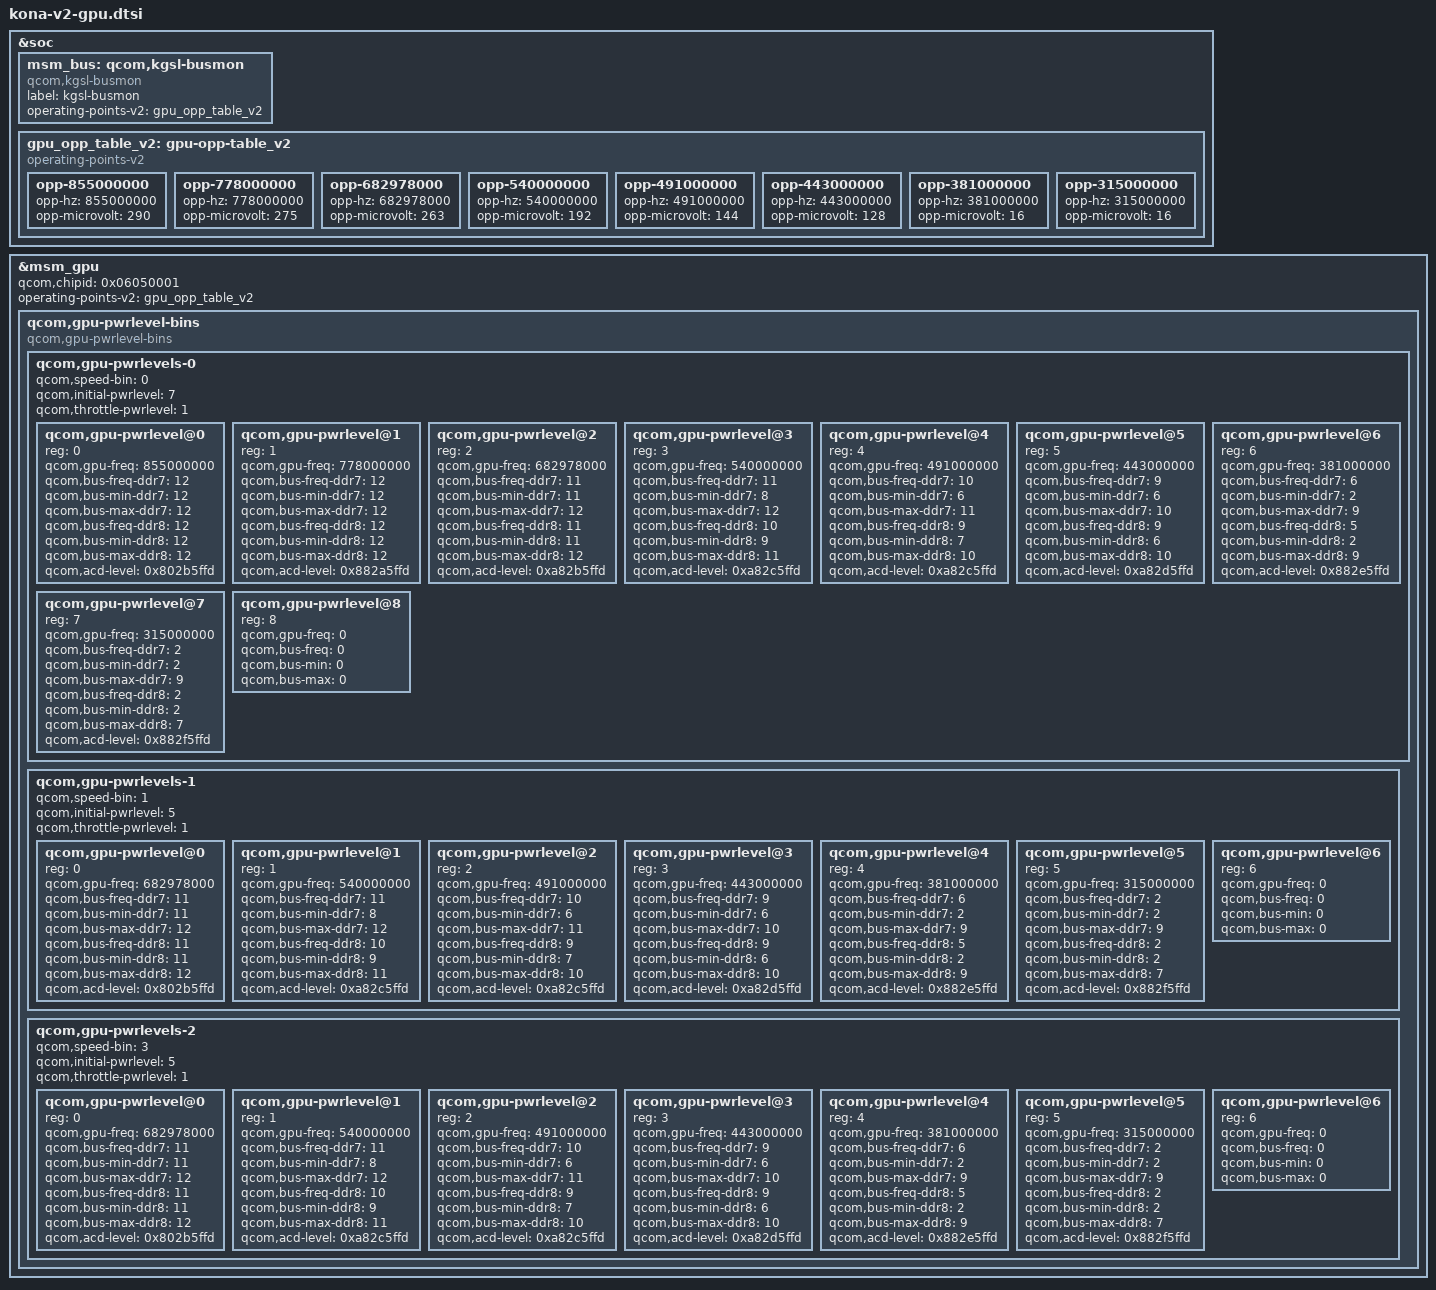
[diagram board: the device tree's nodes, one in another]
&soc {
	msm_bus: qcom,kgsl-busmon {
		label = "kgsl-busmon";
		compatible = "qcom,kgsl-busmon";
		operating-points-v2 = <&gpu_opp_table_v2>;
	};

	gpu_opp_table_v2: gpu-opp-table_v2 {
		compatible = "operating-points-v2";
		
		opp-855000000 {
			opp-hz = /bits/ 64 <855000000>;
			opp-microvolt = <290>;
		};
		
		opp-778000000 {
			opp-hz = /bits/ 64 <778000000>;
			opp-microvolt = <275>;
		};

		opp-682978000 {
			opp-hz = /bits/ 64 <682978000>;
			opp-microvolt = <263>;
		};

		opp-540000000 {
			opp-hz = /bits/ 64 <540000000>;
			opp-microvolt = <192>;
		};

		opp-491000000 {
			opp-hz = /bits/ 64 <491000000>;
			opp-microvolt = <144>;
		};

		opp-443000000 {
			opp-hz = /bits/ 64 <443000000>;
			opp-microvolt = <128>;
		};

		opp-381000000 {
			opp-hz = /bits/ 64 <381000000>;
			opp-microvolt = <16>;
		};

		opp-315000000 {
			opp-hz = /bits/ 64 <315000000>;
			opp-microvolt = <16>;
		};

	};
};

&msm_gpu {
	qcom,chipid = <0x06050001>;

	/* GPU OPP data */
	operating-points-v2 = <&gpu_opp_table_v2>;

	/delete-property/qcom,initial-pwrlevel;
	/delete-node/qcom,gpu-pwrlevels;

	/* Power levels bins */
	qcom,gpu-pwrlevel-bins {
		compatible="qcom,gpu-pwrlevel-bins";
		#address-cells = <1>;
		#size-cells = <0>;

		qcom,gpu-pwrlevels-0 {
			#address-cells = <1>;
			#size-cells = <0>;
			qcom,speed-bin = <0>;
			qcom,initial-pwrlevel = <7>;
			qcom,throttle-pwrlevel = <1>;

			qcom,gpu-pwrlevel@0 {
				reg = <0>;
				qcom,gpu-freq = <855000000>;
				qcom,bus-freq-ddr7 = <12>;
				qcom,bus-min-ddr7 = <12>;
				qcom,bus-max-ddr7 = <12>;

				qcom,bus-freq-ddr8 = <12>;
				qcom,bus-min-ddr8 = <12>;
				qcom,bus-max-ddr8 = <12>;

				qcom,acd-level = <0x802b5ffd>;
			};

			qcom,gpu-pwrlevel@1 {
				reg = <1>;
				qcom,gpu-freq = <778000000>;
				qcom,bus-freq-ddr7 = <12>;
				qcom,bus-min-ddr7 = <12>;
				qcom,bus-max-ddr7 = <12>;

				qcom,bus-freq-ddr8 = <12>;
				qcom,bus-min-ddr8 = <12>;
				qcom,bus-max-ddr8 = <12>;

				qcom,acd-level = <0x882a5ffd>;
			};

			qcom,gpu-pwrlevel@2 {
				reg = <2>;
				qcom,gpu-freq = <682978000>;
				qcom,bus-freq-ddr7 = <11>;
				qcom,bus-min-ddr7 = <11>;
				qcom,bus-max-ddr7 = <12>;

				qcom,bus-freq-ddr8 = <11>;
				qcom,bus-min-ddr8 = <11>;
				qcom,bus-max-ddr8 = <12>;

				qcom,acd-level = <0xa82b5ffd>;
			};

			qcom,gpu-pwrlevel@3 {
				reg = <3>;
				qcom,gpu-freq = <540000000>;
				qcom,bus-freq-ddr7 = <11>;
				qcom,bus-min-ddr7 = <8>;
				qcom,bus-max-ddr7 = <12>;

				qcom,bus-freq-ddr8 = <10>;
				qcom,bus-min-ddr8 = <9>;
				qcom,bus-max-ddr8 = <11>;

				qcom,acd-level = <0xa82c5ffd>;
			};

			qcom,gpu-pwrlevel@4 {
				reg = <4>;
				qcom,gpu-freq = <491000000>;
				qcom,bus-freq-ddr7 = <10>;
				qcom,bus-min-ddr7 = <6>;
				qcom,bus-max-ddr7 = <11>;

				qcom,bus-freq-ddr8 = <9>;
				qcom,bus-min-ddr8 = <7>;
				qcom,bus-max-ddr8 = <10>;

				qcom,acd-level = <0xa82c5ffd>;
			};

			qcom,gpu-pwrlevel@5 {
				reg = <5>;
				qcom,gpu-freq = <443000000>;
				qcom,bus-freq-ddr7 = <9>;
				qcom,bus-min-ddr7 = <6>;
				qcom,bus-max-ddr7 = <10>;

				qcom,bus-freq-ddr8 = <9>;
				qcom,bus-min-ddr8 = <6>;
				qcom,bus-max-ddr8 = <10>;

				qcom,acd-level = <0xa82d5ffd>;
			};

			qcom,gpu-pwrlevel@6 {
				reg = <6>;
				qcom,gpu-freq = <381000000>;
				qcom,bus-freq-ddr7 = <6>;
				qcom,bus-min-ddr7 = <2>;
				qcom,bus-max-ddr7 = <9>;

				qcom,bus-freq-ddr8 = <5>;
				qcom,bus-min-ddr8 = <2>;
				qcom,bus-max-ddr8 = <9>;

				qcom,acd-level = <0x882e5ffd>;
			};

			qcom,gpu-pwrlevel@7 {
				reg = <7>;
				qcom,gpu-freq = <315000000>;
				qcom,bus-freq-ddr7 = <2>;
				qcom,bus-min-ddr7 = <2>;
				qcom,bus-max-ddr7 = <9>;

				qcom,bus-freq-ddr8 = <2>;
				qcom,bus-min-ddr8 = <2>;
				qcom,bus-max-ddr8 = <7>;

				qcom,acd-level = <0x882f5ffd>;
			};

			qcom,gpu-pwrlevel@8 {
				reg = <8>;
				qcom,gpu-freq = <0>;
				qcom,bus-freq = <0>;
				qcom,bus-min = <0>;
				qcom,bus-max = <0>;
			};
		};

		qcom,gpu-pwrlevels-1 {
			#address-cells = <1>;
			#size-cells = <0>;
			qcom,speed-bin = <1>;
			qcom,initial-pwrlevel = <5>;
			qcom,throttle-pwrlevel = <1>;

			qcom,gpu-pwrlevel@0 {
				reg = <0>;
				qcom,gpu-freq = <682978000>;
				qcom,bus-freq-ddr7 = <11>;
				qcom,bus-min-ddr7 = <11>;
				qcom,bus-max-ddr7 = <12>;

				qcom,bus-freq-ddr8 = <11>;
				qcom,bus-min-ddr8 = <11>;
				qcom,bus-max-ddr8 = <12>;

				qcom,acd-level = <0x802b5ffd>;
			};

			qcom,gpu-pwrlevel@1 {
				reg = <1>;
				qcom,gpu-freq = <540000000>;
				qcom,bus-freq-ddr7 = <11>;
				qcom,bus-min-ddr7 = <8>;
				qcom,bus-max-ddr7 = <12>;

				qcom,bus-freq-ddr8 = <10>;
				qcom,bus-min-ddr8 = <9>;
				qcom,bus-max-ddr8 = <11>;

				qcom,acd-level = <0xa82c5ffd>;
			};

			qcom,gpu-pwrlevel@2 {
				reg = <2>;
				qcom,gpu-freq = <491000000>;
				qcom,bus-freq-ddr7 = <10>;
				qcom,bus-min-ddr7 = <6>;
				qcom,bus-max-ddr7 = <11>;

				qcom,bus-freq-ddr8 = <9>;
				qcom,bus-min-ddr8 = <7>;
				qcom,bus-max-ddr8 = <10>;

				qcom,acd-level = <0xa82c5ffd>;
			};

			qcom,gpu-pwrlevel@3 {
				reg = <3>;
				qcom,gpu-freq = <443000000>;
				qcom,bus-freq-ddr7 = <9>;
				qcom,bus-min-ddr7 = <6>;
				qcom,bus-max-ddr7 = <10>;

				qcom,bus-freq-ddr8 = <9>;
				qcom,bus-min-ddr8 = <6>;
				qcom,bus-max-ddr8 = <10>;

				qcom,acd-level = <0xa82d5ffd>;
			};

			qcom,gpu-pwrlevel@4 {
				reg = <4>;
				qcom,gpu-freq = <381000000>;
				qcom,bus-freq-ddr7 = <6>;
				qcom,bus-min-ddr7 = <2>;
				qcom,bus-max-ddr7 = <9>;

				qcom,bus-freq-ddr8 = <5>;
				qcom,bus-min-ddr8 = <2>;
				qcom,bus-max-ddr8 = <9>;

				qcom,acd-level = <0x882e5ffd>;
			};

			qcom,gpu-pwrlevel@5 {
				reg = <5>;
				qcom,gpu-freq = <315000000>;
				qcom,bus-freq-ddr7 = <2>;
				qcom,bus-min-ddr7 = <2>;
				qcom,bus-max-ddr7 = <9>;

				qcom,bus-freq-ddr8 = <2>;
				qcom,bus-min-ddr8 = <2>;
				qcom,bus-max-ddr8 = <7>;

				qcom,acd-level = <0x882f5ffd>;
			};

			qcom,gpu-pwrlevel@6 {
				reg = <6>;
				qcom,gpu-freq = <0>;
				qcom,bus-freq = <0>;
				qcom,bus-min = <0>;
				qcom,bus-max = <0>;
			};
		};

		qcom,gpu-pwrlevels-2 {
			#address-cells = <1>;
			#size-cells = <0>;
			qcom,speed-bin = <3>;
			qcom,initial-pwrlevel = <5>;
			qcom,throttle-pwrlevel = <1>;

			qcom,gpu-pwrlevel@0 {
				reg = <0>;
				qcom,gpu-freq = <682978000>;
				qcom,bus-freq-ddr7 = <11>;
				qcom,bus-min-ddr7 = <11>;
				qcom,bus-max-ddr7 = <12>;

				qcom,bus-freq-ddr8 = <11>;
				qcom,bus-min-ddr8 = <11>;
				qcom,bus-max-ddr8 = <12>;

				qcom,acd-level = <0x802b5ffd>;
			};

			qcom,gpu-pwrlevel@1 {
				reg = <1>;
				qcom,gpu-freq = <540000000>;
				qcom,bus-freq-ddr7 = <11>;
				qcom,bus-min-ddr7 = <8>;
				qcom,bus-max-ddr7 = <12>;

				qcom,bus-freq-ddr8 = <10>;
				qcom,bus-min-ddr8 = <9>;
				qcom,bus-max-ddr8 = <11>;

				qcom,acd-level = <0xa82c5ffd>;
			};

			qcom,gpu-pwrlevel@2 {
				reg = <2>;
				qcom,gpu-freq = <491000000>;
				qcom,bus-freq-ddr7 = <10>;
				qcom,bus-min-ddr7 = <6>;
				qcom,bus-max-ddr7 = <11>;

				qcom,bus-freq-ddr8 = <9>;
				qcom,bus-min-ddr8 = <7>;
				qcom,bus-max-ddr8 = <10>;

				qcom,acd-level = <0xa82c5ffd>;
			};

			qcom,gpu-pwrlevel@3 {
				reg = <3>;
				qcom,gpu-freq = <443000000>;
				qcom,bus-freq-ddr7 = <9>;
				qcom,bus-min-ddr7 = <6>;
				qcom,bus-max-ddr7 = <10>;

				qcom,bus-freq-ddr8 = <9>;
				qcom,bus-min-ddr8 = <6>;
				qcom,bus-max-ddr8 = <10>;

				qcom,acd-level = <0xa82d5ffd>;
			};

			qcom,gpu-pwrlevel@4 {
				reg = <4>;
				qcom,gpu-freq = <381000000>;
				qcom,bus-freq-ddr7 = <6>;
				qcom,bus-min-ddr7 = <2>;
				qcom,bus-max-ddr7 = <9>;

				qcom,bus-freq-ddr8 = <5>;
				qcom,bus-min-ddr8 = <2>;
				qcom,bus-max-ddr8 = <9>;

				qcom,acd-level = <0x882e5ffd>;
			};

			qcom,gpu-pwrlevel@5 {
				reg = <5>;
				qcom,gpu-freq = <315000000>;
				qcom,bus-freq-ddr7 = <2>;
				qcom,bus-min-ddr7 = <2>;
				qcom,bus-max-ddr7 = <9>;

				qcom,bus-freq-ddr8 = <2>;
				qcom,bus-min-ddr8 = <2>;
				qcom,bus-max-ddr8 = <7>;

				qcom,acd-level = <0x882f5ffd>;
			};

			qcom,gpu-pwrlevel@6 {
				reg = <6>;
				qcom,gpu-freq = <0>;
				qcom,bus-freq = <0>;
				qcom,bus-min = <0>;
				qcom,bus-max = <0>;
			};
		};
	};
};
